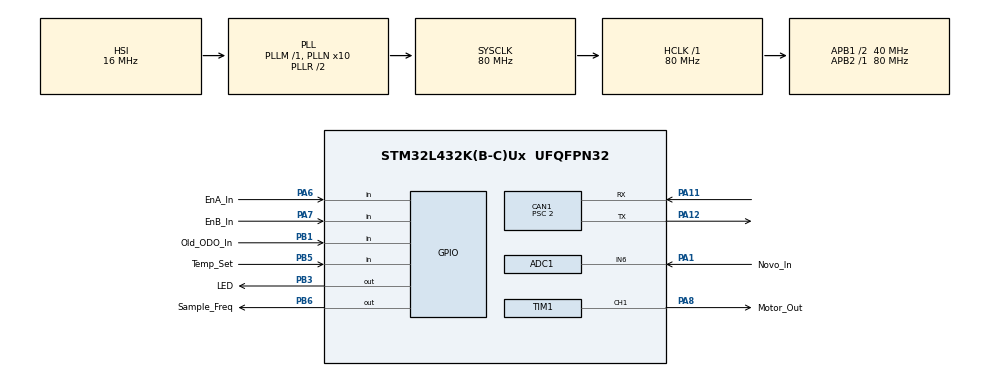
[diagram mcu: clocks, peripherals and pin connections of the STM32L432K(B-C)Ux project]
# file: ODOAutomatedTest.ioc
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ADC1.Channel-1\#ChannelRegularConversion=ADC_CHANNEL_6
ADC1.ExternalTrigConv=ADC_EXTERNALTRIG_T2_TRGO
ADC1.NbrOfConversionFlag=1
ADC1.OffsetNumber-1\#ChannelRegularConversion=ADC_OFFSET_NONE
ADC1.Rank-1\#ChannelRegularConversion=1
ADC1.SamplingTime-1\#ChannelRegularConversion=ADC_SAMPLETIME_2CYCLES_5
ADC1.master=1
CAN1.BS1=CAN_BS1_15TQ
CAN1.BS2=CAN_BS2_4TQ
CAN1.CalculateTimeQuantum=50.0
CAN1.Prescaler=2
CAN1.SJW=CAN_SJW_4TQ
Mcu.Family=STM32L4
Mcu.Name=STM32L432K(B-C)Ux
Mcu.Package=UFQFPN32
NVIC.ADC1_IRQn=true\:1\:0\:true\:false\:true\:true\:true
NVIC.PriorityGroup=NVIC_PRIORITYGROUP_4
NVIC.TIM7_IRQn=true\:2\:0\:true\:false\:true\:true\:true
PA1.GPIO_Label=Novo_In
PA1.Signal=ADCx_IN6
PA11.Mode=Master
PA11.Signal=CAN1_RX
PA12.Mode=Master
PA12.Signal=CAN1_TX
PA13\ (JTMS-SWDIO).GPIO_Label=SWDIO
PA13\ (JTMS-SWDIO).Mode=Serial_Wire
PA13\ (JTMS-SWDIO).Signal=SYS_JTMS-SWDIO
PA14\ (JTCK-SWCLK).GPIO_Label=SWCLK
PA14\ (JTCK-SWCLK).Mode=Serial_Wire
PA14\ (JTCK-SWCLK).Signal=SYS_JTCK-SWCLK
PA6.GPIO_Label=EnA_In
PA6.Signal=GPIO_Input
PA7.GPIO_Label=EnB_In
PA7.Signal=GPIO_Input
PA8.GPIO_Label=Motor_Out
PA8.Signal=S_TIM1_CH1
PB1.GPIO_Label=Old_ODO_In
PB1.Signal=GPIO_Input
PB3\ (JTDO-TRACESWO).GPIO_Label=LED
PB3\ (JTDO-TRACESWO).Signal=GPIO_Output
PB5.GPIO_Label=Temp_Set
PB5.Signal=GPIO_Input
PB6.GPIO_Label=Sample_Freq
PB6.Signal=GPIO_Output
ProjectManager.HeapSize=0x200
ProjectManager.StackSize=0x400
ProjectManager.TargetToolchain=EWARM V8
RCC.ADCFreq_Value=64000000
RCC.AHBFreq_Value=80000000
RCC.APB1CLKDivider=RCC_HCLK_DIV2
RCC.APB1Freq_Value=40000000
RCC.APB1TimFreq_Value=80000000
RCC.APB2Freq_Value=80000000
RCC.APB2TimFreq_Value=80000000
RCC.CortexFreq_Value=80000000
RCC.HCLKFreq_Value=80000000
RCC.HSE_VALUE=8000000
RCC.HSI16_VALUE=16000000
RCC.HSI48_VALUE=48000000
RCC.HSI_VALUE=16000000
RCC.LSE_VALUE=32768
RCC.MSI_VALUE=4000000
RCC.PLLMUL=RCC_PLLMUL_4
RCC.PLLN=10
RCC.PLLSourceVirtual=RCC_PLLSOURCE_HSI
RCC.SYSCLKFreq_VALUE=80000000
RCC.SYSCLKSource=RCC_SYSCLKSOURCE_PLLCLK
RCC.USBFreq_Value=64000000
RCC.VCOOutputFreq_Value=160000000
SH.ADCx_IN6.0=ADC1_IN6,IN6-Single-Ended
SH.S_TIM1_CH1.0=TIM1_CH1,PWM Generation1 CH1
TIM1.Channel-PWM\ Generation1\ CH1=TIM_CHANNEL_1
TIM1.Period=4095
TIM1.Prescaler=0
TIM1.Pulse-PWM\ Generation1\ CH1=0
TIM2.Period=4
TIM2.Prescaler=484
TIM2.TIM_MasterOutputTrigger=TIM_TRGO_UPDATE
TIM7.AutoReloadPreload=TIM_AUTORELOAD_PRELOAD_DISABLE
TIM7.Period=32
TIM7.Prescaler=484
TIM7.TIM_MasterOutputTrigger=TIM_TRGO_RESET
VP_TIM1_VS_ClockSourceITR.Mode=TriggerSource_ITR0
VP_TIM2_VS_ClockSourceINT.Mode=Internal
VP_TIM7_VS_ClockSourceINT.Mode=Enable_Timer
board=NUCLEO-L432KC

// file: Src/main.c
/* USER CODE BEGIN Header */
/**
  ******************************************************************************
  * @file           : main.c
  * @brief          : Main program body
  ******************************************************************************
  * @attention
  *
  * <h2><center>&copy; Copyright (c) 2019 STMicroelectronics.
  * All rights reserved.</center></h2>
  *
  * This software component is licensed by ST under BSD 3-Clause license,
  * the "License"; You may not use this file except in compliance with the
  * License. You may obtain a copy of the License at:
  *                        opensource.org/licenses/BSD-3-Clause
  *
  ******************************************************************************
  */
/* USER CODE END Header */

#include "main.h"
#include "adc.h"
#include "can.h"
#include "tim.h"
#include "gpio.h"

/* USER CODE BEGIN Includes */
#include "ODOAutomatedTest.h"
/* USER CODE END Includes */

void SystemClock_Config(void);

int main(void)
{

  /* MCU Configuration--------------------------------------------------------*/

  /* Reset of all peripherals, Initializes the Flash interface and the Systick. */
  HAL_Init();

  /* Configure the system clock */
  SystemClock_Config();

  /* Initialize all configured peripherals */
  MX_GPIO_Init();
  MX_ADC1_Init();
  MX_TIM1_Init();
  MX_TIM2_Init();
  MX_TIM7_Init();
  MX_CAN1_Init();
  /* USER CODE BEGIN 2 */
  ODO_Init();

  /* USER CODE END 2 */

  /* Infinite loop */
  /* USER CODE BEGIN WHILE */
  while (1)
  {
    ODO_Test_Process();
    /* USER CODE END WHILE */

  }
}

void SystemClock_Config(void)
{
  RCC_OscInitTypeDef RCC_OscInitStruct = {0};
  RCC_ClkInitTypeDef RCC_ClkInitStruct = {0};
  RCC_PeriphCLKInitTypeDef PeriphClkInit = {0};

  /** Initializes the CPU, AHB and APB busses clocks
  */
  RCC_OscInitStruct.OscillatorType = RCC_OSCILLATORTYPE_HSI;
  RCC_OscInitStruct.HSIState = RCC_HSI_ON;
  RCC_OscInitStruct.HSICalibrationValue = RCC_HSICALIBRATION_DEFAULT;
  RCC_OscInitStruct.PLL.PLLState = RCC_PLL_ON;
  RCC_OscInitStruct.PLL.PLLSource = RCC_PLLSOURCE_HSI;
  RCC_OscInitStruct.PLL.PLLM = 1;
  RCC_OscInitStruct.PLL.PLLN = 10;
  RCC_OscInitStruct.PLL.PLLP = RCC_PLLP_DIV7;
  RCC_OscInitStruct.PLL.PLLQ = RCC_PLLQ_DIV2;
  RCC_OscInitStruct.PLL.PLLR = RCC_PLLR_DIV2;
  if (HAL_RCC_OscConfig(&RCC_OscInitStruct) != HAL_OK)
  {
    Error_Handler();
  }
  /** Initializes the CPU, AHB and APB busses clocks
  */
  RCC_ClkInitStruct.ClockType = RCC_CLOCKTYPE_HCLK|RCC_CLOCKTYPE_SYSCLK
                              |RCC_CLOCKTYPE_PCLK1|RCC_CLOCKTYPE_PCLK2;
  RCC_ClkInitStruct.SYSCLKSource = RCC_SYSCLKSOURCE_PLLCLK;
  RCC_ClkInitStruct.AHBCLKDivider = RCC_SYSCLK_DIV1;
  RCC_ClkInitStruct.APB1CLKDivider = RCC_HCLK_DIV2;
  RCC_ClkInitStruct.APB2CLKDivider = RCC_HCLK_DIV1;

  if (HAL_RCC_ClockConfig(&RCC_ClkInitStruct, FLASH_LATENCY_4) != HAL_OK)
  {
    Error_Handler();
  }
  PeriphClkInit.PeriphClockSelection = RCC_PERIPHCLK_ADC;
  PeriphClkInit.AdcClockSelection = RCC_ADCCLKSOURCE_PLLSAI1;
  PeriphClkInit.PLLSAI1.PLLSAI1Source = RCC_PLLSOURCE_HSI;
  PeriphClkInit.PLLSAI1.PLLSAI1M = 1;
  PeriphClkInit.PLLSAI1.PLLSAI1N = 8;
  PeriphClkInit.PLLSAI1.PLLSAI1P = RCC_PLLP_DIV7;
  PeriphClkInit.PLLSAI1.PLLSAI1Q = RCC_PLLQ_DIV2;
  PeriphClkInit.PLLSAI1.PLLSAI1R = RCC_PLLR_DIV2;
  PeriphClkInit.PLLSAI1.PLLSAI1ClockOut = RCC_PLLSAI1_ADC1CLK;
  if (HAL_RCCEx_PeriphCLKConfig(&PeriphClkInit) != HAL_OK)
  {
    Error_Handler();
  }
  /** Configure the main internal regulator output voltage
  */
  if (HAL_PWREx_ControlVoltageScaling(PWR_REGULATOR_VOLTAGE_SCALE1) != HAL_OK)
  {
    Error_Handler();
  }
}

void Error_Handler(void)
{
  /* USER CODE BEGIN Error_Handler_Debug */
  /* User can add his own implementation to report the HAL error return state */
  HAL_GPIO_TogglePin(LED_GPIO_Port, LED_Pin);
  HAL_Delay(1000);
  /* USER CODE END Error_Handler_Debug */
}

/************************ (C) COPYRIGHT STMicroelectronics *****END OF FILE****/
